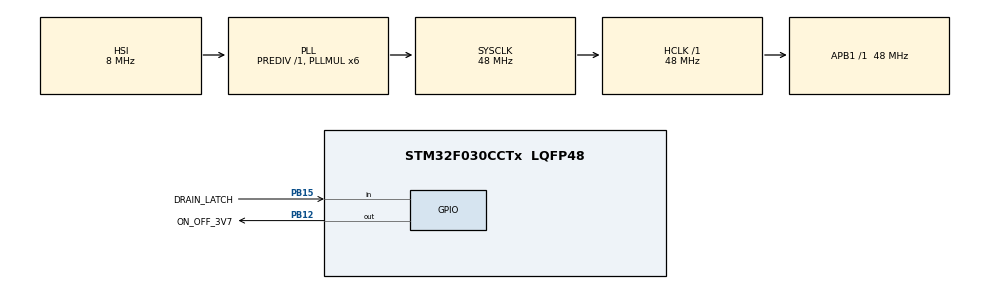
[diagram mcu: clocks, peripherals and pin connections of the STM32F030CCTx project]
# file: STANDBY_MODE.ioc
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Mcu.Family=STM32F0
Mcu.Name=STM32F030CCTx
Mcu.Package=LQFP48
PA0.Mode=SYS_WakeUp0
PA0.Signal=SYS_WKUP1
PA13.Mode=Serial_Wire
PA13.Signal=SYS_SWDIO
PA14.Mode=Serial_Wire
PA14.Signal=SYS_SWCLK
PB12.GPIO_Label=ON_OFF_3V7
PB12.Signal=GPIO_Output
PB15.GPIO_Label=DRAIN_LATCH
PB15.Signal=GPIO_Input
PC13.Mode=SYS_WakeUp1
PC13.Signal=SYS_WKUP2
ProjectManager.HeapSize=0x200
ProjectManager.StackSize=0x400
ProjectManager.TargetToolchain=STM32CubeIDE
RCC.AHBFreq_Value=48000000
RCC.APB1Freq_Value=48000000
RCC.APB1TimFreq_Value=48000000
RCC.HCLKFreq_Value=48000000
RCC.PLLMUL=RCC_PLL_MUL6
RCC.SYSCLKFreq_VALUE=48000000
RCC.SYSCLKSource=RCC_SYSCLKSOURCE_PLLCLK
board=custom

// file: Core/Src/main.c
/* USER CODE BEGIN Header */
/**
  ******************************************************************************
  * @file           : main.c
  * @brief          : Main program body
  ******************************************************************************
  * @attention
  *
  * Copyright (c) 2024 STMicroelectronics.
  * All rights reserved.
  *
  * This software is licensed under terms that can be found in the LICENSE file
  * in the root directory of this software component.
  * If no LICENSE file comes with this software, it is provided AS-IS.
  *
  ******************************************************************************
  */
/* USER CODE END Header */
#include "main.h"

/* USER CODE BEGIN PV */
uint8_t powerSupply=0;
uint8_t gpio=0;
uint32_t contBTN1=0;
/* USER CODE END PV */

void SystemClock_Config(void);
static void MX_GPIO_Init(void);
/* USER CODE BEGIN PFP */
uint8_t control_BTN1(void);
/* USER CODE END PFP */

int main(void)
{

  /* MCU Configuration--------------------------------------------------------*/

  /* Reset of all peripherals, Initializes the Flash interface and the Systick. */
  HAL_Init();

  /* Configure the system clock */
  SystemClock_Config();

  /* Initialize all configured peripherals */
  MX_GPIO_Init();
  /* USER CODE BEGIN 2 */

  /******************** PARA USAR SOLO 1 SYS_WKUP **********************************/
  /*
  //PRESIONAR UNA VEZ Y LISTO (EL PIN PA0 PARECE QUE TIENE RESISTENCIA PULL DOWN, NO SE PUEDE COLCOAR DESDE EL .IOC)
  //verifica la bandera SB la cual es para saber si reanudo
  if(__HAL_PWR_GET_FLAG(PWR_FLAG_SB) != RESET){
	  __HAL_PWR_CLEAR_FLAG(PWR_FLAG_SB);//limpia la bandera

	  //blink led
	  for(uint8_t i=0; i<20; i++){
		  HAL_GPIO_TogglePin(LED_GPIO_Port, LED_Pin);
		  HAL_Delay(150);
	  }

	  //desactivamos el WAKE UP pin
	  HAL_PWR_DisableWakeUpPin(PWR_WAKEUP_PIN1);
  }

  //AHORA RECIEN VAMOS A INGRESAR AL STANDBY MODE
  __HAL_PWR_CLEAR_FLAG(PWR_FLAG_WU);

  for(uint8_t i=0; i<5; i++){
	  HAL_GPIO_TogglePin(LED_GPIO_Port, LED_Pin);
	  HAL_Delay(2000);
  }

  //HABILITAMOS el WAKE UP pin
  HAL_PWR_EnableWakeUpPin(PWR_WAKEUP_PIN1);

  //FINALMENTE INGRESAMOS AL STANDBY MODE
  HAL_PWR_EnterSTANDBYMode();
  */

  /******************** PARA USAR LOS DOS SYS_WKUP **********************************/

  //En este uC estos pines necesitan un pulso 3.3V para ingresar al modo STANDBY
  //es por eso que se coloca una resistencia pull down externa de 1k, no se puede colocar resistencias internas porque no hay esa opcion

  // Verifica si el sistema reanudó desde Standby Mode
  if (__HAL_PWR_GET_FLAG(PWR_FLAG_SB) != RESET) {
      __HAL_PWR_CLEAR_FLAG(PWR_FLAG_SB); // Limpia la bandera

      /*YA QUE CUALQUIER DE ELLOS SE PRESIONA, INMEDIATAMENTE DETECTA SI AUN ESTA PRESIONADO Y ENTRA CUALQUIERA DE LOS IF */

      //Aqui no debe haber nada, ningun codigo, inmediatamente debe pasar a los ifs para detectar el boton presionado

      //Esto hace cuando se presiona el pulsador del SYS_WKUP1
      if (HAL_GPIO_ReadPin(GPIOA, GPIO_PIN_0) == 1) {//FUNCION 1
    	  //AQUI TODO EL CODIGO DE LA FUNCION 1
    	  if (HAL_GPIO_ReadPin(DRAIN_LATCH_GPIO_Port, DRAIN_LATCH_Pin) == 0){
    		  HAL_GPIO_WritePin(ON_OFF_3V7_GPIO_Port, ON_OFF_3V7_Pin, 1);
			  HAL_Delay(4000);//tiempo para apagar luego de encender o viceversa
    	  }else{
    		  HAL_GPIO_WritePin(ON_OFF_3V7_GPIO_Port, ON_OFF_3V7_Pin, 0);
			  HAL_Delay(4000);//tiempo para apagar luego de encender o viceversa
    	  }

      }

      //Esto hace cuando se presiona el pulsador del SYS_WKUP2
      if (HAL_GPIO_ReadPin(GPIOC, GPIO_PIN_13) == 1) {//FUNCION 2
		  for (uint8_t i = 0; i < 120; i++) {
			  HAL_GPIO_TogglePin(ON_OFF_3V7_GPIO_Port, ON_OFF_3V7_Pin);
			  HAL_Delay(50);
		  }
      }

      HAL_PWR_DisableWakeUpPin(PWR_WAKEUP_PIN1);// Desactiva el Wake-Up Pin1
      HAL_PWR_DisableWakeUpPin(PWR_WAKEUP_PIN2);// Desactiva el Wake-Up Pin2
  }

    __HAL_PWR_CLEAR_FLAG(PWR_FLAG_WU);//AHORA RECIEN VAMOS A INGRESAR AL STANDBY MODE
    HAL_PWR_EnableWakeUpPin(PWR_WAKEUP_PIN1);//habilitamos el Wake-Up Pin1
    HAL_PWR_EnableWakeUpPin(PWR_WAKEUP_PIN2);//habilitamos el Wake-Up Pin2
    HAL_PWR_EnterSTANDBYMode();//FINALMENTE INGRESAMOS AL STANDBY MODE

  /* USER CODE END 2 */

  /* Infinite loop */
  while (1)
  {

  }
}

void SystemClock_Config(void)
{
  RCC_OscInitTypeDef RCC_OscInitStruct = {0};
  RCC_ClkInitTypeDef RCC_ClkInitStruct = {0};

  /** Initializes the RCC Oscillators according to the specified parameters
  * in the RCC_OscInitTypeDef structure.
  */
  RCC_OscInitStruct.OscillatorType = RCC_OSCILLATORTYPE_HSI;
  RCC_OscInitStruct.HSIState = RCC_HSI_ON;
  RCC_OscInitStruct.HSICalibrationValue = RCC_HSICALIBRATION_DEFAULT;
  RCC_OscInitStruct.PLL.PLLState = RCC_PLL_ON;
  RCC_OscInitStruct.PLL.PLLSource = RCC_PLLSOURCE_HSI;
  RCC_OscInitStruct.PLL.PLLMUL = RCC_PLL_MUL6;
  RCC_OscInitStruct.PLL.PREDIV = RCC_PREDIV_DIV1;
  if (HAL_RCC_OscConfig(&RCC_OscInitStruct) != HAL_OK)
  {
    Error_Handler();
  }

  /** Initializes the CPU, AHB and APB buses clocks
  */
  RCC_ClkInitStruct.ClockType = RCC_CLOCKTYPE_HCLK|RCC_CLOCKTYPE_SYSCLK
                              |RCC_CLOCKTYPE_PCLK1;
  RCC_ClkInitStruct.SYSCLKSource = RCC_SYSCLKSOURCE_PLLCLK;
  RCC_ClkInitStruct.AHBCLKDivider = RCC_SYSCLK_DIV1;
  RCC_ClkInitStruct.APB1CLKDivider = RCC_HCLK_DIV1;

  if (HAL_RCC_ClockConfig(&RCC_ClkInitStruct, FLASH_LATENCY_1) != HAL_OK)
  {
    Error_Handler();
  }
}

static void MX_GPIO_Init(void)
{
  GPIO_InitTypeDef GPIO_InitStruct = {0};

  /* GPIO Ports Clock Enable */
  __HAL_RCC_GPIOC_CLK_ENABLE();
  __HAL_RCC_GPIOA_CLK_ENABLE();
  __HAL_RCC_GPIOB_CLK_ENABLE();

  /*Configure GPIO pin Output Level */
  HAL_GPIO_WritePin(ON_OFF_3V7_GPIO_Port, ON_OFF_3V7_Pin, GPIO_PIN_RESET);

  /*Configure GPIO pin : ON_OFF_3V7_Pin */
  GPIO_InitStruct.Pin = ON_OFF_3V7_Pin;
  GPIO_InitStruct.Mode = GPIO_MODE_OUTPUT_PP;
  GPIO_InitStruct.Pull = GPIO_NOPULL;
  GPIO_InitStruct.Speed = GPIO_SPEED_FREQ_LOW;
  HAL_GPIO_Init(ON_OFF_3V7_GPIO_Port, &GPIO_InitStruct);

  /*Configure GPIO pin : DRAIN_LATCH_Pin */
  GPIO_InitStruct.Pin = DRAIN_LATCH_Pin;
  GPIO_InitStruct.Mode = GPIO_MODE_INPUT;
  GPIO_InitStruct.Pull = GPIO_NOPULL;
  HAL_GPIO_Init(DRAIN_LATCH_GPIO_Port, &GPIO_InitStruct);

}

void Error_Handler(void)
{
  __disable_irq();
  while (1)
  {
  }
}
